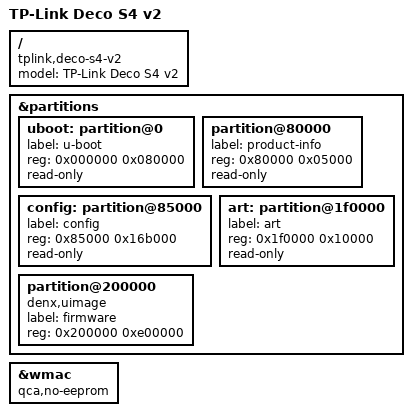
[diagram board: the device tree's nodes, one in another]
// SPDX-License-Identifier: GPL-2.0-or-later OR MIT

#include <dt-bindings/gpio/gpio.h>
#include <dt-bindings/input/input.h>

#include "qca9563_tplink_deco.dtsi"

/ {
	compatible = "tplink,deco-s4-v2", "qca,qca9563";
	model = "TP-Link Deco S4 v2";
};

&partitions {
	uboot: partition@0 {
		label = "u-boot";
		reg = <0x000000 0x080000>;
		read-only;
	};

	partition@80000 {
		label = "product-info";
		reg = <0x80000 0x05000>;
		read-only;
	};

	config: partition@85000 {
		label = "config";
		reg = <0x85000 0x16b000>;
		read-only;
	};

	art: partition@1f0000 {
		label = "art";
		reg = <0x1f0000 0x10000>;
		read-only;
	};

	partition@200000 {
		compatible = "denx,uimage";
		label = "firmware";
		reg = <0x200000 0xe00000>;
	};
};

&wmac {
	qca,no-eeprom;
};
